VERSION ""

NS_ :

BS_:

BU_: Var PLC E4V PC

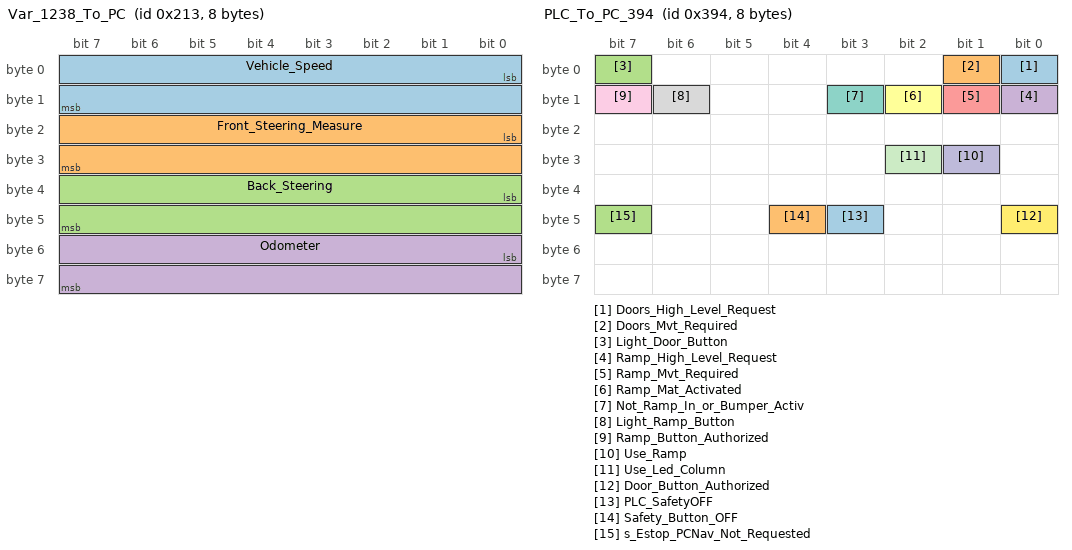
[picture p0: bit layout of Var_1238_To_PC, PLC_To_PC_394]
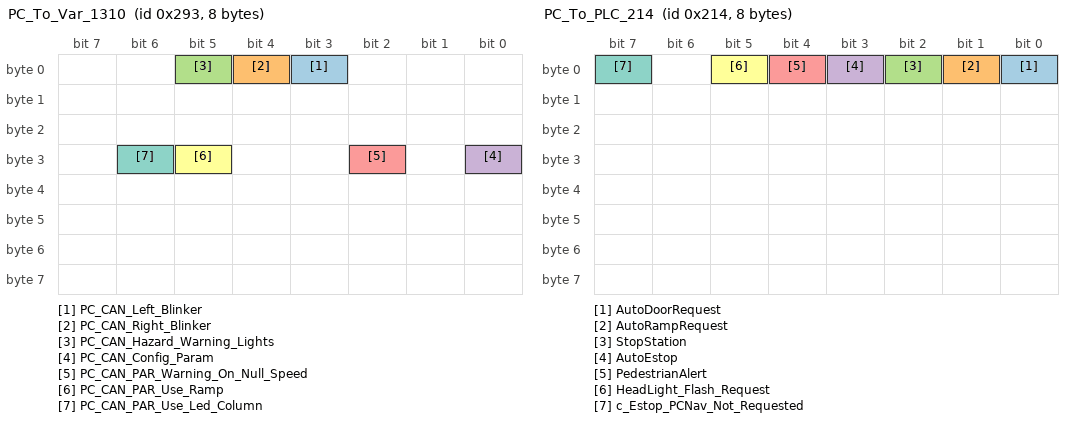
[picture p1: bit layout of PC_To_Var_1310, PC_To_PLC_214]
BO_ 531 Var_1238_To_PC: 8 None
 SG_ Vehicle_Speed : 0|16@1- (0.001,0.0) [-32768|32767] "m/s" Vector__XXX
 SG_ Front_Steering_Measure : 16|16@1- (0.0001,0.0) [-32768|32767] "rad" Vector__XXX
 SG_ Back_Steering : 32|16@1- (0.0001,0.0) [-32768|32767] "rad" Vector__XXX
 SG_ Odometer : 48|16@1+ (1.0,0.0) [0|65535] "km" Vector__XXX

BO_ 916 PLC_To_PC_394: 8 None
 SG_ Doors_High_Level_Request : 0|1@1+ (1.0,0.0) [0|1] "" Vector__XXX
 SG_ Doors_Mvt_Required : 1|1@1+ (1.0,0.0) [0|1] "" Vector__XXX
 SG_ Light_Door_Button : 7|1@1+ (1.0,0.0) [0|1] "" Vector__XXX
 SG_ Ramp_High_Level_Request : 8|1@1+ (1.0,0.0) [0|1] "" Vector__XXX
 SG_ Ramp_Mvt_Required : 9|1@1+ (1.0,0.0) [0|1] "" Vector__XXX
 SG_ Ramp_Mat_Activated : 10|1@1+ (1.0,0.0) [0|1] "" Vector__XXX
 SG_ Not_Ramp_In_or_Bumper_Activ : 11|1@1+ (1.0,0.0) [0|1] "" Vector__XXX
 SG_ Light_Ramp_Button : 14|1@1+ (1.0,0.0) [0|1] "" Vector__XXX
 SG_ Ramp_Button_Authorized : 15|1@1+ (1.0,0.0) [0|1] "" Vector__XXX
 SG_ Use_Ramp : 25|1@1+ (1.0,0.0) [0|1] "" Vector__XXX
 SG_ Use_Led_Column : 26|1@1+ (1.0,0.0) [0|1] "" Vector__XXX
 SG_ Door_Button_Authorized : 40|1@1+ (1.0,0.0) [0|1] "" Vector__XXX
 SG_ PLC_SafetyOFF : 43|1@1+ (1.0,0.0) [0|1] "" Vector__XXX
 SG_ Safety_Button_OFF : 44|1@1+ (1.0,0.0) [0|1] "" Vector__XXX
 SG_ s_Estop_PCNav_Not_Requested : 47|1@1+ (1.0,0.0) [0|1] "" Vector__XXX

BO_ 660 PLC_To_PC_294: 8 None
 SG_ Automatic_Mode_EStop_Source : 28|1@1+ (1.0,0.0) [0|1] "" Vector__XXX
 SG_ Automatic_Mode_EStop : 29|1@1+ (1.0,0.0) [0|1] "" Vector__XXX
 SG_ High_Level_Flash_Light_Command : 58|1@1+ (1.0,0.0) [0|1] "" Vector__XXX
 SG_ High_Level_Tram_Bell_Command : 59|1@1+ (1.0,0.0) [0|1] "" Vector__XXX
 SG_ Out2_RL : 0|1@1+ (1.0,0.0) [0|1] "" Vector__XXX
 SG_ Out2_RR : 1|1@1+ (1.0,0.0) [0|1] "" Vector__XXX
 SG_ Out2_FL : 2|1@1+ (1.0,0.0) [0|1] "" Vector__XXX
 SG_ Out2_FR : 3|1@1+ (1.0,0.0) [0|1] "" Vector__XXX
 SG_ Out3_RL : 4|1@1+ (1.0,0.0) [0|1] "" Vector__XXX
 SG_ Out3_RR : 5|1@1+ (1.0,0.0) [0|1] "" Vector__XXX
 SG_ Out3_FL : 6|1@1+ (1.0,0.0) [0|1] "" Vector__XXX
 SG_ Out3_FR : 7|1@1+ (1.0,0.0) [0|1] "" Vector__XXX
 SG_ Front_I1 : 8|1@1+ (1.0,0.0) [0|1] "" Vector__XXX
 SG_ Front_I2 : 9|1@1+ (1.0,0.0) [0|1] "" Vector__XXX
 SG_ Front_I3 : 10|1@1+ (1.0,0.0) [0|1] "" Vector__XXX
 SG_ Front_I4 : 11|1@1+ (1.0,0.0) [0|1] "" Vector__XXX
 SG_ Rear_I1 : 12|1@1+ (1.0,0.0) [0|1] "" Vector__XXX
 SG_ Rear_I2 : 13|1@1+ (1.0,0.0) [0|1] "" Vector__XXX
 SG_ Rear_I3 : 14|1@1+ (1.0,0.0) [0|1] "" Vector__XXX
 SG_ Rear_I4 : 15|1@1+ (1.0,0.0) [0|1] "" Vector__XXX

BO_ 404 PLC_To_PC_194: 8 None
 SG_ Rearming_Authorized : 7|1@1+ (1.0,0.0) [0|1] "" Vector__XXX
 SG_ DoorsOpened : 8|1@1+ (1.0,0.0) [0|1] "" Vector__XXX
 SG_ DoorsClosed : 9|1@1+ (1.0,0.0) [0|1] "" Vector__XXX
 SG_ DoorsObstacle : 10|1@1+ (1.0,0.0) [0|1] "" Vector__XXX
 SG_ DoorsFatalFailure : 11|1@1+ (1.0,0.0) [0|1] "" Vector__XXX
 SG_ DoorsNOKforTraction : 14|1@1+ (1.0,0.0) [0|1] "" Vector__XXX
 SG_ DoorsDefaults : 15|1@1+ (1.0,0.0) [0|1] "" Vector__XXX
 SG_ EStop_Buttons : 16|1@1+ (1.0,0.0) [0|1] "" Vector__XXX
 SG_ EStop_Manual_State : 17|1@1+ (1.0,0.0) [0|1] "" Vector__XXX
 SG_ EStop_Manual_Button : 18|1@1+ (1.0,0.0) [0|1] "" Vector__XXX
 SG_ Safety_Disabled : 19|1@1+ (1.0,0.0) [0|1] "" Vector__XXX
 SG_ Manual_Mode_ON : 23|1@1+ (1.0,0.0) [0|1] "" Vector__XXX
 SG_ Front_Steering_No_Fault : 24|1@1+ (1.0,0.0) [0|1] "" Vector__XXX
 SG_ Rear_Steering_No_Fault : 25|1@1+ (1.0,0.0) [0|1] "" Vector__XXX
 SG_ Brake_Controller_Fault : 26|1@1+ (1.0,0.0) [0|1] "" Vector__XXX
 SG_ Traction_Authorized : 27|1@1+ (1.0,0.0) [0|1] "" Vector__XXX
 SG_ Coders_Indicate_Vhc_Stopped : 30|1@1+ (1.0,0.0) [0|1] "" Vector__XXX
 SG_ Vehicle_Stopped_3_States : 31|1@1+ (1.0,0.0) [0|1] "" Vector__XXX
 SG_ Vehicle_Stopped_4_States : 33|1@1+ (1.0,0.0) [0|1] "" Vector__XXX
 SG_ El_Pkg_Brk_Engaged : 34|1@1+ (1.0,0.0) [0|1] "" Vector__XXX
 SG_ EM_Pkg_Brk_Engaged : 35|1@1+ (1.0,0.0) [0|1] "" Vector__XXX
 SG_ EStop_Not_Required : 38|1@1+ (1.0,0.0) [0|1] "" Vector__XXX
 SG_ RampIn : 40|1@1+ (1.0,0.0) [0|1] "" Vector__XXX
 SG_ RampOut : 41|1@1+ (1.0,0.0) [0|1] "" Vector__XXX
 SG_ RampMoving : 42|1@1+ (1.0,0.0) [0|1] "" Vector__XXX
 SG_ RampDefaults : 43|1@1+ (1.0,0.0) [0|1] "" Vector__XXX
 SG_ RampNOKForTraction : 44|1@1+ (1.0,0.0) [0|1] "" Vector__XXX
 SG_ RampSuspensionEnabled : 45|1@1+ (1.0,0.0) [0|1] "" Vector__XXX
 SG_ RampNotIn : 46|1@1+ (1.0,0.0) [0|1] "" Vector__XXX
 SG_ RampNotOut : 47|1@1+ (1.0,0.0) [0|1] "" Vector__XXX
 SG_ Alert_Battery_Low : 52|1@1+ (1.0,0.0) [0|1] "" Vector__XXX
 SG_ Soft_Stop_Battery_Low : 55|1@1+ (1.0,0.0) [0|1] "" Vector__XXX
 SG_ Rearming_Required : 57|1@1+ (1.0,0.0) [0|1] "" Vector__XXX
 SG_ LMS_FrontLeft_Detection : 0|1@1+ (1.0,0.0) [0|1] "" Vector__XXX
 SG_ LMS_FrontRight_Detection : 1|1@1+ (1.0,0.0) [0|1] "" Vector__XXX
 SG_ LMS_RearLeft_Detection : 2|1@1+ (1.0,0.0) [0|1] "" Vector__XXX
 SG_ LMS_RearRight_Detection : 3|1@1+ (1.0,0.0) [0|1] "" Vector__XXX
 SG_ Obstacle_Detected : 4|1@1+ (1.0,0.0) [0|1] "" Vector__XXX
 SG_ LMS_Operational : 5|1@1+ (1.0,0.0) [0|1] "" Vector__XXX
 SG_ Obstacle_Detected_NoSafety : 6|1@1+ (1.0,0.0) [0|1] "" Vector__XXX

 BO_ 659 PC_To_Var_1310: 8 None
 SG_ PC_CAN_Left_Blinker : 3|1@1+ (1.0,0.0) [0|1] "" Vector__XXX
 SG_ PC_CAN_Right_Blinker : 4|1@1+ (1.0,0.0) [0|1] "" Vector__XXX
 SG_ PC_CAN_Hazard_Warning_Lights : 5|1@1+ (1.0,0.0) [0|1] "" Vector__XXX
 SG_ PC_CAN_Config_Param : 24|1@1+ (1.0,0.0) [0|1] "" Vector__XXX
 SG_ PC_CAN_PAR_Warning_On_Null_Speed : 26|1@1+ (1.0,0.0) [0|1] "" Vector__XXX
 SG_ PC_CAN_PAR_Use_Ramp : 29|1@1+ (1.0,0.0) [0|1] "" Vector__XXX
 SG_ PC_CAN_PAR_Use_Led_Column : 30|1@1+ (1.0,0.0) [0|1] "" Vector__XXX

BO_ 532 PC_To_PLC_214: 8 None
 SG_ AutoDoorRequest : 0|1@1+ (1.0,0.0) [0|1] "" Vector__XXX
 SG_ AutoRampRequest : 1|1@1+ (1.0,0.0) [0|1] "" Vector__XXX
 SG_ StopStation : 2|1@1+ (1.0,0.0) [0|1] "" Vector__XXX
 SG_ AutoEstop : 3|1@1+ (1.0,0.0) [0|1] "" Vector__XXX
 SG_ PedestrianAlert : 4|1@1+ (1.0,0.0) [0|1] "" Vector__XXX
 SG_ HeadLight_Flash_Request : 5|1@1+ (1.0,0.0) [0|1] "" Vector__XXX
 SG_ c_Estop_PCNav_Not_Requested : 7|1@1+ (1.0,0.0) [0|1] "" Vector__XXX

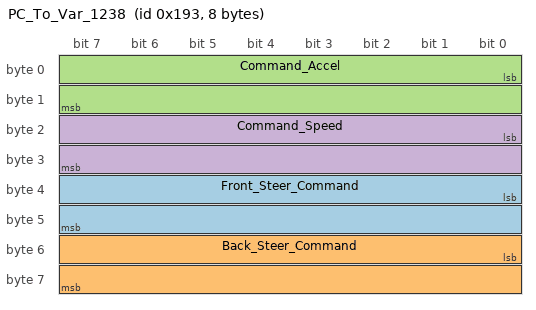
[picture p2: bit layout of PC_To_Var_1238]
BO_ 403 PC_To_Var_1238: 8 None
 SG_ Front_Steer_Command : 32|16@1- (0.0001,0.0) [-32768|32767] "rad" Vector__XXX
 SG_ Back_Steer_Command : 48|16@1- (0.0001,0.0) [-32768|32767] "rad" Vector__XXX
 SG_ Command_Accel : 0|16@1- (0.001,0.0) [-32768|32767] "m/s²" Vector__XXX
 SG_ Command_Speed : 16|16@1- (0.001,0.0) [-32768|32767] "m/s" Vector__XXX

BO_ 1408 E4V_580: 8 None
 SG_ E4V_Percentage : 40|8@1+ (1.0,0.0) [0|255] "%" Vector__XXX

BA_DEF_   "DBName" STRING ;
BA_DEF_   "BusType" STRING ;
BA_DEF_ BO_  "GenMsgCycleTime" INT 0 3600000;
BA_DEF_ BO_  "VFrameFormat" ENUM "StandardCAN","ExtendedCAN","reserved","J1939PG";
BA_DEF_DEF_  "DBName" "";
BA_DEF_DEF_  "BusType" "CAN";
BA_DEF_DEF_  "GenMsgCycleTime" 0;
BA_DEF_DEF_  "VFrameFormat" "J1939PG";
BA_ "DBName" "Name";
BA_ "VFrameFormat" BO_ 531 0;
BA_ "VFrameFormat" BO_ 916 0;
BA_ "VFrameFormat" BO_ 660 0;
BA_ "VFrameFormat" BO_ 404 0;
BA_ "VFrameFormat" BO_ 659 0;
BA_ "VFrameFormat" BO_ 532 0;
BA_ "VFrameFormat" BO_ 403 0;
BA_ "VFrameFormat" BO_ 1408 0;
